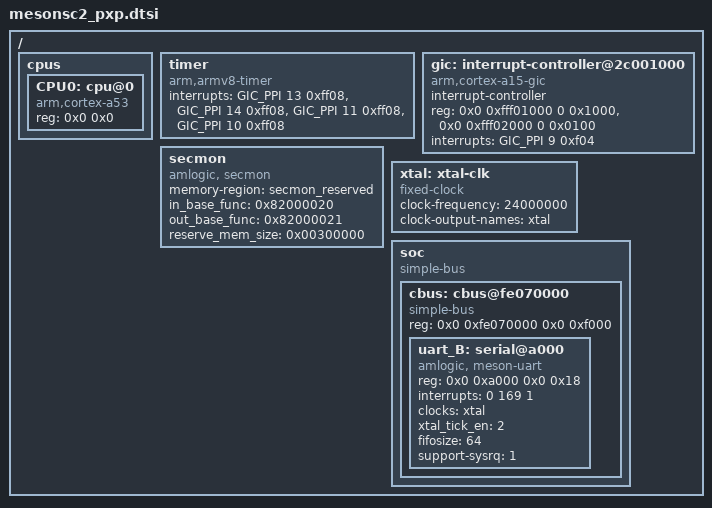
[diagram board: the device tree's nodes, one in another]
/*
 * arch/arm64/boot/dts/amlogic/mesonsm1.dtsi
 *
 * Copyright (C) 2017 Amlogic, Inc. All rights reserved.
 *
 * This program is free software; you can redistribute it and/or modify
 * it under the terms of the GNU General Public License as published by
 * the Free Software Foundation; either version 2 of the License, or
 * (at your option) any later version.
 *
 * This program is distributed in the hope that it will be useful, but WITHOUT
 * ANY WARRANTY; without even the implied warranty of MERCHANTABILITY or
 * FITNESS FOR A PARTICULAR PURPOSE.  See the GNU General Public License for
 * more details.
 *
 */

#include <dt-bindings/interrupt-controller/arm-gic.h>
#include <dt-bindings/clock/amlogic,g12a-clkc.h>
#include <dt-bindings/gpio/meson-g12a-gpio.h>
#include <dt-bindings/gpio/gpio.h>

/ {
	cpus:cpus {
		#address-cells = <2>;
		#size-cells = <0>;

		CPU0:cpu@0 {
			device_type = "cpu";
			compatible = "arm,cortex-a53","arm,armv8";
			reg = <0x0 0x0>;
		};
	};

	timer {
		compatible = "arm,armv8-timer";
		interrupts = <GIC_PPI 13 0xff08>,
				<GIC_PPI 14 0xff08>,
				<GIC_PPI 11 0xff08>,
				<GIC_PPI 10 0xff08>;
	};

	gic: interrupt-controller@2c001000 {
		compatible = "arm,cortex-a15-gic", "arm,cortex-a9-gic";
		#interrupt-cells = <3>;
		#address-cells = <0>;
		interrupt-controller;
		reg = <0x0 0xfff01000 0 0x1000>,
		      <0x0 0xfff02000 0 0x0100>;
		interrupts = <GIC_PPI 9 0xf04>;
	};

	secmon {
		compatible = "amlogic, secmon";
		memory-region = <&secmon_reserved>;
		in_base_func = <0x82000020>;
		out_base_func = <0x82000021>;
		reserve_mem_size = <0x00300000>;
	};

	xtal: xtal-clk {
		compatible = "fixed-clock";
		clock-frequency = <24000000>;
		clock-output-names = "xtal";
		#clock-cells = <0>;
	};
	soc {
		compatible = "simple-bus";
		#address-cells = <2>;
		#size-cells = <2>;
		ranges;

		cbus: cbus@fe070000 {
			compatible = "simple-bus";
			reg = <0x0 0xfe070000 0x0 0xf000>;
			#address-cells = <2>;
			#size-cells = <2>;
			ranges = <0x0 0x0 0x0 0xfe070000 0x0 0xf000>;

			uart_B: serial@a000 {
				compatible = "amlogic, meson-uart";
				reg = <0x0 0xa000 0x0 0x18>;
				interrupts = <0 169 1>;
				status = "okay";
				clocks = <&xtal>;
				clock-names = "clk_uart";
				xtal_tick_en = <2>;
				fifosize = < 64 >;
				pinctrl-names = "default";
				/*pinctrl-0 = <&ao_uart_pins>;*/
				support-sysrq = <1>;  /* 0 not support*/
			};
		};
	};
};
